AUTOSAR XML (schema 00046)
package /ComponentTypes
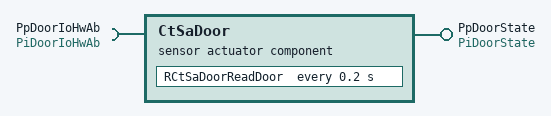
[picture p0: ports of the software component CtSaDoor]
  sensor actuator sw component type CtSaDoor
    provide port PpDoorState: nonqueued-sender-com-spec{data-element=DeDoorState, init-value=constant-reference=CDoorClosed}, provided-interface=PiDoorState
    require port PpDoorIoHwAb: client-com-spec=ReadChannel, required-interface=PiDoorIoHwAb
    behavior CtSaDoor_InternalBehavior: data-type-mapping=DemoTypeMapping, supports-multiple-instantiation=true
      timing event TMT_RCtSaDoorReadDoor: start-on-event=RCtSaDoorReadDoor, period=0.2
      runnable RCtSaDoorReadDoor
        data-send-points:
          access SEND_PpDoorState_DeDoorState: accessed-variable=PpDoorState.DeDoorState
  swc implementation CtSaDoor_Implementation: behavior=CtSaDoor_InternalBehavior
